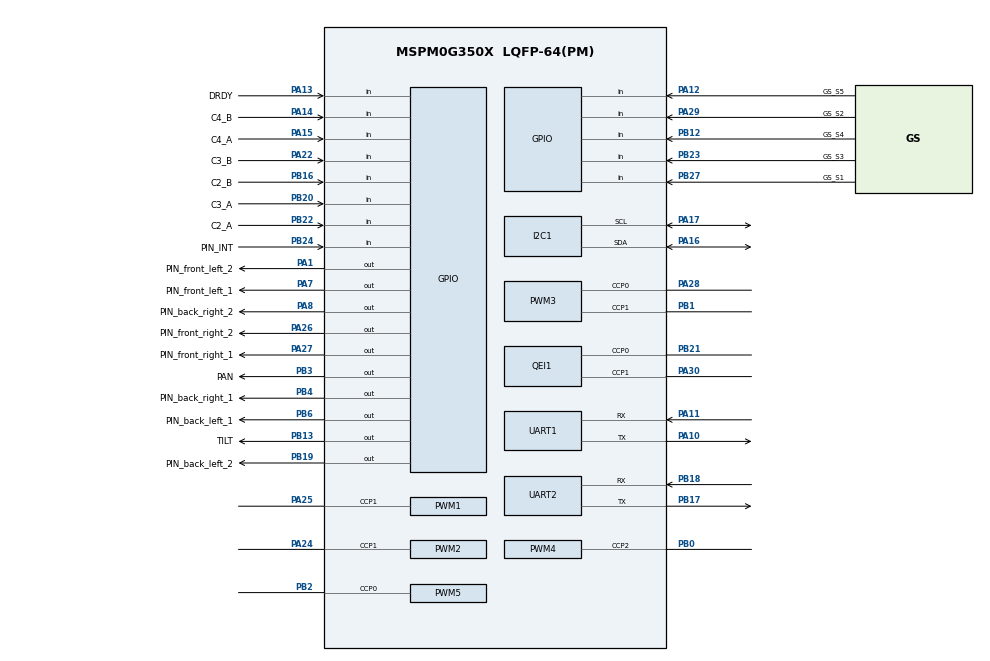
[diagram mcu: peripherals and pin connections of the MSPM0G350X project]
/**
 * @cliArgs --device "MSPM0G350X" --part "Default" --package "LQFP-64(PM)" --product "mspm0_sdk@2.11.00.07"
 * @versions {"tool":"1.26.2+4477"}
 */

/**
 * Import the modules used in this configuration.
 */
const GPIO   = scripting.addModule("/ti/driverlib/GPIO", {}, false);
const GPIO1  = GPIO.addInstance();
const GPIO2  = GPIO.addInstance();
const GPIO3  = GPIO.addInstance();
const GPIO4  = GPIO.addInstance();
const GPIO5  = GPIO.addInstance();
const I2C    = scripting.addModule("/ti/driverlib/I2C", {}, false);
const I2C1   = I2C.addInstance();
const PWM    = scripting.addModule("/ti/driverlib/PWM", {}, false);
const PWM1   = PWM.addInstance();
const PWM2   = PWM.addInstance();
const PWM3   = PWM.addInstance();
const PWM4   = PWM.addInstance();
const PWM5   = PWM.addInstance();
const QEI    = scripting.addModule("/ti/driverlib/QEI", {}, false);
const QEI1   = QEI.addInstance();
const SYSCTL = scripting.addModule("/ti/driverlib/SYSCTL");
const UART   = scripting.addModule("/ti/driverlib/UART", {}, false);
const UART1  = UART.addInstance();
const UART2  = UART.addInstance();

/**
 * Write custom configuration values to the imported modules.
 */
GPIO1.$name                         = "GPIO_ENCODER";
GPIO1.associatedPins.create(6);
GPIO1.associatedPins[0].$name       = "C2_A";
GPIO1.associatedPins[0].direction   = "INPUT";
GPIO1.associatedPins[0].pin.$assign = "PB22";
GPIO1.associatedPins[1].$name       = "C2_B";
GPIO1.associatedPins[1].direction   = "INPUT";
GPIO1.associatedPins[1].pin.$assign = "PB16";
GPIO1.associatedPins[2].$name       = "C3_A";
GPIO1.associatedPins[2].direction   = "INPUT";
GPIO1.associatedPins[2].pin.$assign = "PB20";
GPIO1.associatedPins[3].$name       = "C3_B";
GPIO1.associatedPins[3].direction   = "INPUT";
GPIO1.associatedPins[3].pin.$assign = "PA22";
GPIO1.associatedPins[4].$name       = "C4_A";
GPIO1.associatedPins[4].direction   = "INPUT";
GPIO1.associatedPins[4].pin.$assign = "PA15";
GPIO1.associatedPins[5].$name       = "C4_B";
GPIO1.associatedPins[5].direction   = "INPUT";
GPIO1.associatedPins[5].pin.$assign = "PA14";

const Board = scripting.addModule("/ti/driverlib/Board", {}, false);

GPIO2.$name                         = "GPIO_GRAYSCALE";
GPIO2.associatedPins.create(5);
GPIO2.associatedPins[0].$name       = "GS_S1";
GPIO2.associatedPins[0].direction   = "INPUT";
GPIO2.associatedPins[0].pin.$assign = "PB27";
GPIO2.associatedPins[1].$name       = "GS_S2";
GPIO2.associatedPins[1].direction   = "INPUT";
GPIO2.associatedPins[1].pin.$assign = "PA29";
GPIO2.associatedPins[2].$name       = "GS_S3";
GPIO2.associatedPins[2].direction   = "INPUT";
GPIO2.associatedPins[2].pin.$assign = "PB23";
GPIO2.associatedPins[3].$name       = "GS_S4";
GPIO2.associatedPins[3].direction   = "INPUT";
GPIO2.associatedPins[3].pin.$assign = "PB12";
GPIO2.associatedPins[4].$name       = "GS_S5";
GPIO2.associatedPins[4].direction   = "INPUT";
GPIO2.associatedPins[4].pin.$assign = "PA12";

GPIO3.$name                         = "GPIO_MOTOR";
GPIO3.associatedPins.create(8);
GPIO3.associatedPins[0].$name       = "PIN_back_left_1";
GPIO3.associatedPins[0].pin.$assign = "PB6";
GPIO3.associatedPins[1].$name       = "PIN_back_left_2";
GPIO3.associatedPins[1].pin.$assign = "PB19";
GPIO3.associatedPins[2].$name       = "PIN_back_right_1";
GPIO3.associatedPins[2].pin.$assign = "PB4";
GPIO3.associatedPins[3].$name       = "PIN_back_right_2";
GPIO3.associatedPins[3].pin.$assign = "PA8";
GPIO3.associatedPins[4].$name       = "PIN_front_left_1";
GPIO3.associatedPins[4].pin.$assign = "PA7";
GPIO3.associatedPins[5].$name       = "PIN_front_left_2";
GPIO3.associatedPins[5].pin.$assign = "PA1";
GPIO3.associatedPins[6].$name       = "PIN_front_right_1";
GPIO3.associatedPins[6].pin.$assign = "PA27";
GPIO3.associatedPins[7].$name       = "PIN_front_right_2";
GPIO3.associatedPins[7].pin.$assign = "PA26";

GPIO4.$name                         = "cloud_direction";
GPIO4.associatedPins.create(2);
GPIO4.associatedPins[0].$name       = "TILT";
GPIO4.associatedPins[0].pin.$assign = "PB13";
GPIO4.associatedPins[1].$name       = "PAN";
GPIO4.associatedPins[1].pin.$assign = "PB3";

GPIO5.$name                         = "GPIO_MPU_INT";
GPIO5.associatedPins.create(2);
GPIO5.associatedPins[0].$name       = "PIN_INT";
GPIO5.associatedPins[0].direction   = "INPUT";
GPIO5.associatedPins[0].pin.$assign = "PB24";
GPIO5.associatedPins[1].$name       = "DRDY";
GPIO5.associatedPins[1].direction   = "INPUT";
GPIO5.associatedPins[1].pin.$assign = "PA13";

I2C1.$name                             = "I2C_1";
I2C1.peripheral.$assign                = "I2C1";
I2C1.peripheral.sdaPin.$assign         = "PA16";
I2C1.peripheral.sclPin.$assign         = "PA17";
I2C1.sdaPinConfig.$name                = "ti_driverlib_gpio_GPIOPinGeneric12";
I2C1.sdaPinConfig.hideOutputInversion  = scripting.forceWrite(false);
I2C1.sdaPinConfig.onlyInternalResistor = scripting.forceWrite(false);
I2C1.sdaPinConfig.passedPeripheralType = scripting.forceWrite("Digital");
I2C1.sclPinConfig.$name                = "ti_driverlib_gpio_GPIOPinGeneric13";
I2C1.sclPinConfig.hideOutputInversion  = scripting.forceWrite(false);
I2C1.sclPinConfig.onlyInternalResistor = scripting.forceWrite(false);
I2C1.sclPinConfig.passedPeripheralType = scripting.forceWrite("Digital");

PWM1.$name                              = "PWM_front_right";
PWM1.timerCount                         = 1600;
PWM1.pwmMode                            = "EDGE_ALIGN_UP";
PWM1.ccIndex                            = [1];
PWM1.ccp1PinConfig.$name                = "ti_driverlib_gpio_GPIOPinGeneric7";
PWM1.ccp1PinConfig.direction            = scripting.forceWrite("OUTPUT");
PWM1.ccp1PinConfig.hideOutputInversion  = scripting.forceWrite(false);
PWM1.ccp1PinConfig.onlyInternalResistor = scripting.forceWrite(false);
PWM1.ccp1PinConfig.passedPeripheralType = scripting.forceWrite("Digital");
PWM1.peripheral.$assign                 = "TIMG12";
PWM1.peripheral.ccp1Pin.$assign         = "PA25";
PWM1.PWM_CHANNEL_1.$name                = "ti_driverlib_pwm_PWMTimerCC0";
PWM1.PWM_CHANNEL_1.initVal              = "HIGH";

PWM2.$name                              = "PWM_back_right";
PWM2.timerCount                         = 1600;
PWM2.pwmMode                            = "EDGE_ALIGN_UP";
PWM2.ccIndex                            = [1];
PWM2.ccp1PinConfig.$name                = "ti_driverlib_gpio_GPIOPinGeneric8";
PWM2.ccp1PinConfig.direction            = scripting.forceWrite("OUTPUT");
PWM2.ccp1PinConfig.hideOutputInversion  = scripting.forceWrite(false);
PWM2.ccp1PinConfig.onlyInternalResistor = scripting.forceWrite(false);
PWM2.ccp1PinConfig.passedPeripheralType = scripting.forceWrite("Digital");
PWM2.peripheral.$assign                 = "TIMG7";
PWM2.peripheral.ccp1Pin.$assign         = "PA24";
PWM2.PWM_CHANNEL_1.$name                = "ti_driverlib_pwm_PWMTimerCC1";
PWM2.PWM_CHANNEL_1.initVal              = "HIGH";

PWM3.$name                              = "PWM_left";
PWM3.timerCount                         = 1600;
PWM3.pwmMode                            = "EDGE_ALIGN_UP";
PWM3.peripheral.$assign                 = "TIMA1";
PWM3.peripheral.ccp0Pin.$assign         = "PA28";
PWM3.peripheral.ccp1Pin.$assign         = "PB1";
PWM3.PWM_CHANNEL_0.$name                = "ti_driverlib_pwm_PWMTimerCC2";
PWM3.PWM_CHANNEL_0.initVal              = "HIGH";
PWM3.PWM_CHANNEL_1.$name                = "ti_driverlib_pwm_PWMTimerCC3";
PWM3.PWM_CHANNEL_1.initVal              = "HIGH";
PWM3.ccp0PinConfig.$name                = "ti_driverlib_gpio_GPIOPinGeneric6";
PWM3.ccp0PinConfig.direction            = scripting.forceWrite("OUTPUT");
PWM3.ccp0PinConfig.hideOutputInversion  = scripting.forceWrite(false);
PWM3.ccp0PinConfig.onlyInternalResistor = scripting.forceWrite(false);
PWM3.ccp0PinConfig.passedPeripheralType = scripting.forceWrite("Digital");
PWM3.ccp1PinConfig.$name                = "ti_driverlib_gpio_GPIOPinGeneric9";
PWM3.ccp1PinConfig.direction            = scripting.forceWrite("OUTPUT");
PWM3.ccp1PinConfig.hideOutputInversion  = scripting.forceWrite(false);
PWM3.ccp1PinConfig.onlyInternalResistor = scripting.forceWrite(false);
PWM3.ccp1PinConfig.passedPeripheralType = scripting.forceWrite("Digital");

PWM4.$name                      = "cloud_1_TILT";
PWM4.pwmMode                    = "EDGE_ALIGN_UP";
PWM4.ccIndex                    = [2];
PWM4.peripheral.$assign         = "TIMA0";
PWM4.peripheral.ccp2Pin.$assign = "PB0";
PWM4.PWM_CHANNEL_2.$name        = "ti_driverlib_pwm_PWMTimerCC4";
PWM4.ccp2PinConfig.$name        = "ti_driverlib_gpio_GPIOPinGeneric10";

PWM5.$name                              = "cloud_2_PAN";
PWM5.pwmMode                            = "EDGE_ALIGN_UP";
PWM5.ccIndex                            = [0];
PWM5.PWM_CHANNEL_0.$name                = "ti_driverlib_pwm_PWMTimerCC5";
PWM5.ccp0PinConfig.$name                = "ti_driverlib_gpio_GPIOPinGeneric11";
PWM5.ccp0PinConfig.direction            = scripting.forceWrite("OUTPUT");
PWM5.ccp0PinConfig.hideOutputInversion  = scripting.forceWrite(false);
PWM5.ccp0PinConfig.onlyInternalResistor = scripting.forceWrite(false);
PWM5.ccp0PinConfig.passedPeripheralType = scripting.forceWrite("Digital");
PWM5.peripheral.$assign                 = "TIMG6";
PWM5.peripheral.ccp0Pin.$assign         = "PB2";

QEI1.$name                              = "TIMG8";
QEI1.peripheral.$assign                 = "TIMG8";
QEI1.peripheral.ccp0Pin.$assign         = "PB21";
QEI1.peripheral.ccp1Pin.$assign         = "PA30";
QEI1.ccp0PinConfig.$name                = "ti_driverlib_gpio_GPIOPinGeneric0";
QEI1.ccp0PinConfig.hideOutputInversion  = scripting.forceWrite(false);
QEI1.ccp0PinConfig.onlyInternalResistor = scripting.forceWrite(false);
QEI1.ccp0PinConfig.passedPeripheralType = scripting.forceWrite("Digital");
QEI1.ccp1PinConfig.$name                = "ti_driverlib_gpio_GPIOPinGeneric1";
QEI1.ccp1PinConfig.hideOutputInversion  = scripting.forceWrite(false);
QEI1.ccp1PinConfig.onlyInternalResistor = scripting.forceWrite(false);
QEI1.ccp1PinConfig.passedPeripheralType = scripting.forceWrite("Digital");

SYSCTL.forceDefaultClkConfig = true;

UART1.$name                    = "UART_0";
UART1.targetBaudRate           = 115200;
UART1.peripheral.$assign       = "UART0";
UART1.peripheral.rxPin.$assign = "PA11";
UART1.peripheral.txPin.$assign = "PA10";
UART1.txPinConfig.$name        = "ti_driverlib_gpio_GPIOPinGeneric2";
UART1.rxPinConfig.$name        = "ti_driverlib_gpio_GPIOPinGeneric3";

UART2.targetBaudRate                   = 115200;
UART2.$name                            = "camera";
UART2.peripheral.$assign               = "UART2";
UART2.peripheral.rxPin.$assign         = "PB18";
UART2.peripheral.txPin.$assign         = "PB17";
UART2.txPinConfig.$name                = "ti_driverlib_gpio_GPIOPinGeneric4";
UART2.txPinConfig.direction            = scripting.forceWrite("OUTPUT");
UART2.txPinConfig.hideOutputInversion  = scripting.forceWrite(false);
UART2.txPinConfig.onlyInternalResistor = scripting.forceWrite(false);
UART2.txPinConfig.passedPeripheralType = scripting.forceWrite("Digital");
UART2.rxPinConfig.$name                = "ti_driverlib_gpio_GPIOPinGeneric5";
UART2.rxPinConfig.hideOutputInversion  = scripting.forceWrite(false);
UART2.rxPinConfig.onlyInternalResistor = scripting.forceWrite(false);
UART2.rxPinConfig.passedPeripheralType = scripting.forceWrite("Digital");

/**
 * Pinmux solution for unlocked pins/peripherals. This ensures that minor changes to the automatic solver in a future
 * version of the tool will not impact the pinmux you originally saw.  These lines can be completely deleted in order to
 * re-solve from scratch.
 */
Board.peripheral.$suggestSolution          = "DEBUGSS";
Board.peripheral.swclkPin.$suggestSolution = "PA20";
Board.peripheral.swdioPin.$suggestSolution = "PA19";
SYSCTL.peripheral.$suggestSolution         = "SYSCTL";
